# RA2A1 register map
Vendor: Renesas Electronics Corporation; Series: RA2; File version: 1.1
CPU: other r1p0, little endian, MPU, no FPU, VTOR, 2 interrupt priority bits
Registers are 8-bit, read-write, reset 0x0 unless marked. A register's access mark holds for its fields unless they carry their own. Offsets are from the block's base; [hi:lo] are bit positions; {n}, {i} and the like mark numbered series; 'fields as' and 'values as' point back to an identical list.

## OPAMP — OperationalAmplifier
Base 0x40086800
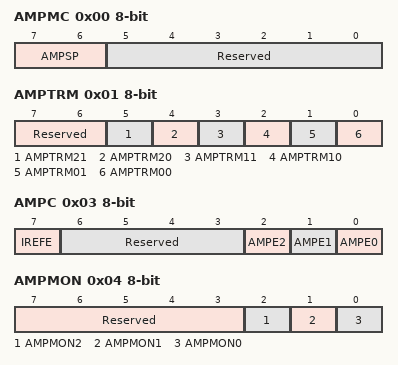
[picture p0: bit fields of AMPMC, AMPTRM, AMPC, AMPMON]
0x00 AMPMC — Operational amplifier mode control register
  [7:6] AMPSP — OPAMP Operation mode selection
    0=Low-power mode (Low-speed); 2=Low-power mode (Low-speed); 1=Middle-speed mode; 3=High-speed mode
  [5:0] Reserved — These bits are read as 000000. The write value should be 000000.
0x01 AMPTRM — Operational amplifier trigger mode control register
  [7:6] Reserved — These bits are read as 00. The write value should be 00.
  [5] AMPTRM21 — OPAMP function activation/stop trigger control
    0=Software trigger mode(AMPTRM20=0)/An activation trigger mode(AMPTRM20=1); 1=Setting prohibited(AMPTRM20=0)/An activation and A/D trigger mode(AMPTRM20=1)
  [4] AMPTRM20 — OPAMP function activation/stop trigger control
    0=Software trigger mode(AMPTRM21=0)/Setting prohibited(AMPTRM21=1); 1=An activation trigger mode(AMPTRM21=0)/An activation and A/D trigger mode(AMPTRM21=1)
  [3] AMPTRM11 — OPAMP function activation/stop trigger control
    0=Software trigger mode(AMPTRM10=0)/An activation trigger mode(AMPTRM10=1); 1=Setting prohibited(AMPTRM10=0)/An activation and A/D trigger mode(AMPTRM10=1)
  [2] AMPTRM10 — OPAMP function activation/stop trigger control
    0=Software trigger mode(AMPTRM11=0)/Setting prohibited(AMPTRM11=1); 1=An activation trigger mode(AMPTRM11=0)/An activation and A/D trigger mode(AMPTRM11=1)
  [1] AMPTRM01 — OPAMP function activation/stop trigger control
    0=Software trigger mode(AMPTRM00=0)/An activation trigger mode(AMPTRM00=1); 1=Setting prohibited(AMPTRM00=0)/An activation and A/D trigger mode(AMPTRM00=1)
  [0] AMPTRM00 — OPAMP function activation/stop trigger control
    0=Software trigger mode(AMPTRM01=0)/Setting prohibited(AMPTRM01=1); 1=An activation trigger mode(AMPTRM01=0)/An activation and A/D trigger mode(AMPTRM01=1)
0x02 AMPTRS — Operational Amplifier Activation Trigger Select Register
  [1:0] AMPTRS — Activation Trigger SelectionNote: Do not change the value of the AMPTRS register after setting the AMPTRM register.
    0=OPAMPn: OPAMP activation trigger n (n = 0 to 2); 1=OPAMPn: OPAMP activation trigger 0 (n = 0, 1), OPAMP2: OPAMP activation trigger 1; 2=Setting prohibited; 3=OPAMPn: OPAMP activation trigger 0 (n = 0 to 2)
0x03 AMPC — Operational amplifier control register
  [7] IREFE — Reference Current Circuit Operation Control
    0=Reference current circuit is stopped; 1=Operation of reference current circuit is enabled
  [6:3] Reserved — These bits are read as 0000. The write value should be 0000.
  [2] AMPE2 — Operation control of operational amplifier 2
    0=OPAMP is stopped; 1=OPAMP is enabled
  [1] AMPE1 — Operation control of operational amplifier 1
    0=OPAMP is stopped; 1=OPAMP is enabled
  [0] AMPE0 — Operation control of operational amplifier 0
    0=OPAMP is stopped; 1=OPAMP is enabled
0x04 AMPMON ro — Operational amplifier monitor register
  [7:3] Reserved — These bits are read as 00000.
  [2] AMPMON2 — OPAMP2 Status
    0=OPAMP is stopped; 1=OPAMP is operating
  [1] AMPMON1 — OPAMP1 Status
    0=OPAMP is stopped; 1=OPAMP is operating
  [0] AMPMON0 — OPAMP0 Status
    0=OPAMP is stopped; 1=OPAMP is operating
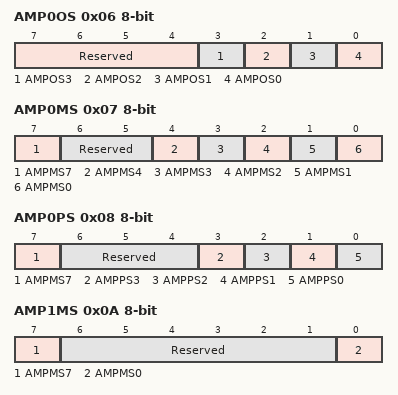
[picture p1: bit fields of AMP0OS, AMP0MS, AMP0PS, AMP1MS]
0x06 AMP0OS — Operational Amplifier 0 Output Select Register
  [7:4] Reserved — These bits are read as 0000. The write value should be 0000.
  [3] AMPOS3 — AMP2+ pin select
    0=AMP2+ pin is not connected to the OPAMP0 output; 1=AMP2+ pin is connected to the OPAMP0 output
  [2] AMPOS2 — AMP2- pin select
    0=AMP2- pin is not connected to the OPAMP0 output; 1=AMP2- pin is connected to the OPAMP0 output
  [1] AMPOS1 — AMP1+ pin select
    0=AMP1+ pin is not connected to the OPAMP0 output; 1=AMP1+ pin is connected to the OPAMP0 output
  [0] AMPOS0 — AMP1- pin select
    0=AMP1- pin is not connected to the OPAMP0 output; 1=AMP1- pin is connected to the OPAMP0 output
0x07 AMP0MS — Operational Amplifier 0 Minus Input Select Register
  [7] AMPMS7 — OPAMP0 output select
    0=OPAMP0 output is not connected to the AMP0 minus input; 1=OPAMP0 output is connected to the AMP0 minus input
  [6:5] Reserved — These bits are read as 00. The write value should be 00.
  [4] AMPMS4 — AMP2- pin select
    0=AMP2- pin is not connected to the AMP0 minus input; 1=AMP2- pin is connected to the AMP0 minus input
  [3] AMPMS3 — AMP1+ pin select
    0=AMP1+ pin is not connected to the AMP0 minus input; 1=AMP1+ pin is connected to the AMP0 minus input
  [2] AMPMS2 — AMP1- pin select
    0=AMP1- pin is not connected to the AMP0 minus input; 1=AMP1- pin is connected to the AMP0 minus input
  [1] AMPMS1 — AMP0+ pin select
    0=AMP0+ pin is not connected to the AMP0 minus input; 1=AMP0+ pin is connected to the AMP0 minus input
  [0] AMPMS0 — AMP0- pin select
    0=AMP0- pin is not connected to the AMP0 minus input; 1=AMP0- pin is connected to the AMP0 minus input
0x08 AMP0PS — Operational Amplifier 0 Plus Input Select Register
  [7] AMPMS7 — DAC12 output select
    0=DAC12 output is not connected to the AMP0 plus input; 1=DAC12 output is connected to the AMP0 plus input
  [6:4] Reserved — These bits are read as 000. The write value should be 000.
  [3] AMPPS3 — AMP2+ pin select
    0=AMP2+ pin is not connected to the AMP0 plus input; 1=AMP2+ pin is connected to the AMP0 plus input
  [2] AMPPS2 — AMP1+pin select
    0=AMP1+ pin is not connected to the AMP0 plus input; 1=AMP1+ pin is connected to the AMP0 plus input
  [1] AMPPS1 — AMP1- pin select
    0=AMP1- pin is not connected to the AMP0 plus input; 1=AMP1- pin is connected to the AMP0 plus input
  [0] AMPPS0 — AMP0+ pin select
    0=AMP0+ pin is not connected to the AMP0 plus input; 1=AMP0+ pin is connected to the AMP0 plus input
0x0A AMP1MS — Operational Amplifier 1 Minus Input Select Register
  [7] AMPMS7 — OPAMP1 output select
    0=OPAMP1 output is not connected to the AMP1 minus input; 1=OPAMP1 output is connected to the AMP1 minus input
  [6:1] Reserved — These bits are read as 000000. The write value should be 000000.
  [0] AMPMS0 — AMP1- pin select
    0=AMP1- pin is not connected to the AMP1 minus input; 1=AMP1- pin is connected to the AMP1 minus input
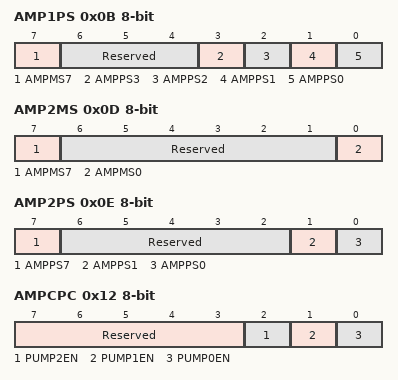
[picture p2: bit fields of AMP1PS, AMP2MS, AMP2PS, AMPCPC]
0x0B AMP1PS — Operational Amplifier 1 Plus Input Select Register
  [7] AMPMS7 — OPAMP2 output select
    0=OPAMP2 output is not connected to the AMP2 minus input; 1=OPAMP2 output is connected to the AMP2 minus input
  [6:4] Reserved — These bits are read as 000. The write value should be 000.
  [3] AMPPS3 — AMP2+ pin select
    0=AMP2+ pin is not connected to the AMP1 plus input; 1=AMP2+ pin is connected to the AMP1
  [2] AMPPS2 — AMP2- pin select
    0=AMP2- pin is not connected to the AMP1 plus input; 1=AMP2- pin is connected to the AMP1 plus input
  [1] AMPPS1 — AMP1+ pin select
    0=AMP1+ pin is not connected to the AMP1 plus input; 1=AMP1+ pin is connected to the AMP1 plus input
  [0] AMPPS0 — AMP1- pin select
    0=AMP1- pin is not connected to the AMP1 plus input; 1=AMP1- pin is connected to the AMP1 plus input
0x0D AMP2MS — Operational Amplifier 2 Minus Input Select Register
  [7] AMPMS7 — OPAMP2 output select
    values as AMP1PS.AMPMS7
  [6:1] Reserved — These bits are read as 000000. The write value should be 000000.
  [0] AMPMS0 — AMP2- pin select
    0=AMP2- pin is not connected to the AMP2 minus input; 1=AMP2- pin is connected to the AMP2 minus input
0x0E AMP2PS — Operational Amplifier 2 Plus Input Select Register
  [7] AMPPS7 — DAC8 channel 1output select
    0=DAC8 channel 1 output is not connected to the AMP2 plus input; 1=DAC8 channel 1 output is connected to the AMP2 plus input
  [6:2] Reserved — These bits are read as 00000. The write value should be 00000.
  [1] AMPPS1 — AMP2+ pin select
    0=AMP2+ pin is not connected to the AMP2 plus input; 1=AMP2+ pin is connected to the AMP2 plus input
  [0] AMPPS0 — AMP2- pin select
    0=AMP2- pin is not connected to the AMP2 plus input; 1=AMP2- pin is connected to the AMP2 plus input
0x12 AMPCPC — Operational Amplifier Switch Charge Pump Control Register
  [7:3] Reserved — These bits are read as 00000. The write value should be 00000.
  [2] PUMP2EN — Charge Pump for AMP2 Enable
    0=Charge Pump for the AMP2 disabled; 1=Charge Pump for the AMP2 enable
  [1] PUMP1EN — Charge Pump for AMP1 Enable
    0=Charge Pump for the AMP1 disabled; 1=Charge Pump for the AMP1 enable
  [0] PUMP0EN — Charge Pump for AMP0 Enable
    0=Charge Pump for the AMP0 disabled; 1=Charge Pump for the AMP0 enable
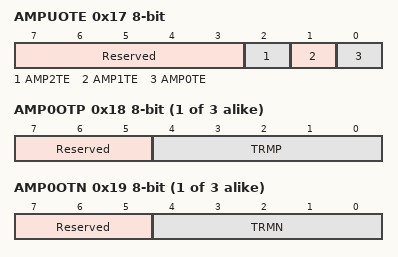
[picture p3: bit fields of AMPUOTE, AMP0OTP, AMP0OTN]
0x17 AMPUOTE — Operational Amplifier User Offset Trimming Enable Register
  [7:3] Reserved — These bits are read as 00000. The write value should be 00000.
  [2] AMP2TE — AMP2OT write enable
    0=Not possible to write to the AMP2OTP and AMP2OTN registers; 1=Possible to write to the AMP2OTP and AMP2OTN registers
  [1] AMP1TE — AMP1OT write enable
    0=Not possible to write to the AMP1OTP and AMP1OTN registers; 1=Possible to write to the AMP1OTP and AMP1OTN registers
  [0] AMP0TE — AMP0OT write enable
    0=Not possible to write to the AMP0OTP and AMP0OTN registers; 1=Possible to write to the AMP0OTP and AMP0OTN registers
{0x18+2i} AMP{i}OTP (reset mask 0xE0) (i=0..2) — Operational Amplifier {i} Offset Trimming Pch Register
  [7:5] Reserved — These bits are read as 000. The write value should be 000.
  [4:0] TRMP — AMP{i} input offset trimming Pch side
{0x19+2i} AMP{i}OTN (reset mask 0xE0) (i=0..2) — Operational Amplifier {i} Offset Trimming Nch Register
  [7:5] Reserved — These bits are read as 000. The write value should be 000.
  [4:0] TRMN — AMP{i} input offset trimming Nch side
